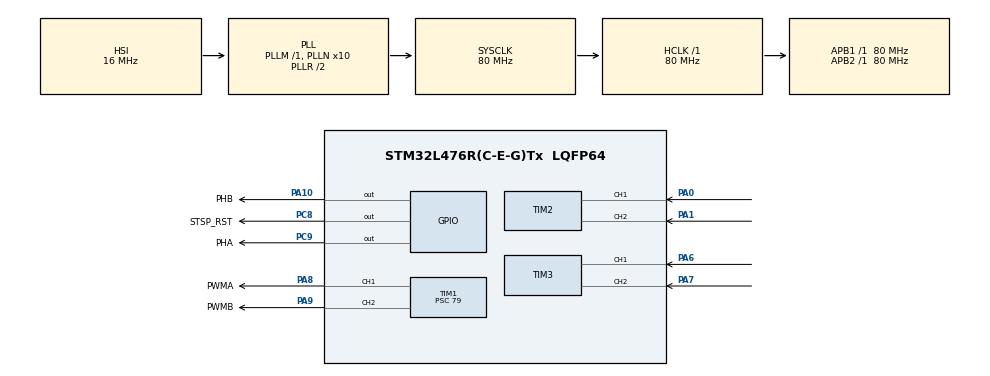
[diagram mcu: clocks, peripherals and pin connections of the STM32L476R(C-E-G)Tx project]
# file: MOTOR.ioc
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Mcu.Family=STM32L4
Mcu.Name=STM32L476R(C-E-G)Tx
Mcu.Package=LQFP64
NVIC.PriorityGroup=NVIC_PRIORITYGROUP_4
PA0.Signal=S_TIM2_CH1
PA1.Signal=S_TIM2_CH2
PA10.GPIO_Label=PHB
PA10.Signal=GPIO_Output
PA13\ (JTMS-SWDIO).Mode=Serial_Wire
PA13\ (JTMS-SWDIO).Signal=SYS_JTMS-SWDIO
PA14\ (JTCK-SWCLK).Mode=Serial_Wire
PA14\ (JTCK-SWCLK).Signal=SYS_JTCK-SWCLK
PA6.Signal=S_TIM3_CH1
PA7.Signal=S_TIM3_CH2
PA8.GPIO_Label=PWMA
PA8.Signal=S_TIM1_CH1
PA9.GPIO_Label=PWMB
PA9.Signal=S_TIM1_CH2
PC8.GPIO_Label=STSP_RST
PC8.Signal=GPIO_Output
PC9.GPIO_Label=PHA
PC9.Signal=GPIO_Output
ProjectManager.HeapSize=0x200
ProjectManager.StackSize=0x400
ProjectManager.TargetToolchain=MDK-ARM V5.32
RCC.ADCFreq_Value=64000000
RCC.AHBFreq_Value=80000000
RCC.APB1Freq_Value=80000000
RCC.APB1TimFreq_Value=80000000
RCC.APB2Freq_Value=80000000
RCC.APB2TimFreq_Value=80000000
RCC.CortexFreq_Value=80000000
RCC.HCLKFreq_Value=80000000
RCC.HSE_VALUE=8000000
RCC.HSI_VALUE=16000000
RCC.LSE_VALUE=32768
RCC.MSI_VALUE=4000000
RCC.PLLN=10
RCC.PLLSourceVirtual=RCC_PLLSOURCE_HSI
RCC.SYSCLKFreq_VALUE=80000000
RCC.SYSCLKSource=RCC_SYSCLKSOURCE_PLLCLK
RCC.USBFreq_Value=64000000
RCC.VCOOutputFreq_Value=160000000
SH.S_TIM1_CH1.0=TIM1_CH1,PWM Generation1 CH1
SH.S_TIM1_CH2.0=TIM1_CH2,PWM Generation2 CH2
SH.S_TIM2_CH1.0=TIM2_CH1,Encoder_Interface
SH.S_TIM2_CH2.0=TIM2_CH2,Encoder_Interface
SH.S_TIM3_CH1.0=TIM3_CH1,Encoder_Interface
SH.S_TIM3_CH2.0=TIM3_CH2,Encoder_Interface
TIM1.Channel-PWM\ Generation1\ CH1=TIM_CHANNEL_1
TIM1.Channel-PWM\ Generation2\ CH2=TIM_CHANNEL_2
TIM1.Prescaler=79
TIM2.EncoderMode=TIM_ENCODERMODE_TI12
TIM3.EncoderMode=TIM_ENCODERMODE_TI12
VP_TIM1_VS_ClockSourceINT.Mode=Internal
board=custom

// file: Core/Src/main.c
/* USER CODE BEGIN Header */
/**
  ******************************************************************************
  * @file           : main.c
  * @brief          : Main program body
  ******************************************************************************
  * @attention
  *
  * Copyright (c) 2026 STMicroelectronics.
  * All rights reserved.
  *
  * This software is licensed under terms that can be found in the LICENSE file
  * in the root directory of this software component.
  * If no LICENSE file comes with this software, it is provided AS-IS.
  *
  ******************************************************************************
  */
/* USER CODE END Header */
#include "main.h"

/* USER CODE BEGIN Includes */
#include "motor.h"
#include "encoder.h"

/* USER CODE END Includes */

TIM_HandleTypeDef htim1;
TIM_HandleTypeDef htim2;
TIM_HandleTypeDef htim3;

/* USER CODE BEGIN PV */
MOTOR MotorA;
MOTOR MotorB;
/* USER CODE END PV */

void SystemClock_Config(void);
static void MX_GPIO_Init(void);
static void MX_TIM1_Init(void);
static void MX_TIM2_Init(void);
static void MX_TIM3_Init(void);

int main(void)
{

  /* MCU Configuration--------------------------------------------------------*/

  /* Reset of all peripherals, Initializes the Flash interface and the Systick. */
  HAL_Init();

  /* Configure the system clock */
  SystemClock_Config();

  /* Initialize all configured peripherals */
  MX_GPIO_Init();
  MX_TIM1_Init();
  MX_TIM2_Init();
  MX_TIM3_Init();
  /* USER CODE BEGIN 2 */
	motor_init(&MotorA, &htim1, TIM_CHANNEL_1, STSP_RST_GPIO_Port, STSP_RST_Pin,
	PHA_GPIO_Port, PHA_Pin, PWMA_GPIO_Port, PWMA_Pin);
	motor_init(&MotorB, &htim1, TIM_CHANNEL_2, STSP_RST_GPIO_Port, STSP_RST_Pin,
	PHB_GPIO_Port, PHB_Pin, PWMB_GPIO_Port, PWMB_Pin);

	enable_motor(&MotorA);
	enable_motor(&MotorB);
  /* USER CODE END 2 */

  /* Infinite loop */
  while (1)
  {

    /* USER CODE BEGIN 3 */
		set_speed(&MotorA, -500);
		set_speed(&MotorB, 500);
  }
  /* USER CODE END 3 */
}

void SystemClock_Config(void)
{
  RCC_OscInitTypeDef RCC_OscInitStruct = {0};
  RCC_ClkInitTypeDef RCC_ClkInitStruct = {0};

  /** Configure the main internal regulator output voltage
  */
  if (HAL_PWREx_ControlVoltageScaling(PWR_REGULATOR_VOLTAGE_SCALE1) != HAL_OK)
  {
    Error_Handler();
  }

  /** Initializes the RCC Oscillators according to the specified parameters
  * in the RCC_OscInitTypeDef structure.
  */
  RCC_OscInitStruct.OscillatorType = RCC_OSCILLATORTYPE_HSI;
  RCC_OscInitStruct.HSIState = RCC_HSI_ON;
  RCC_OscInitStruct.HSICalibrationValue = RCC_HSICALIBRATION_DEFAULT;
  RCC_OscInitStruct.PLL.PLLState = RCC_PLL_ON;
  RCC_OscInitStruct.PLL.PLLSource = RCC_PLLSOURCE_HSI;
  RCC_OscInitStruct.PLL.PLLM = 1;
  RCC_OscInitStruct.PLL.PLLN = 10;
  RCC_OscInitStruct.PLL.PLLP = RCC_PLLP_DIV7;
  RCC_OscInitStruct.PLL.PLLQ = RCC_PLLQ_DIV2;
  RCC_OscInitStruct.PLL.PLLR = RCC_PLLR_DIV2;
  if (HAL_RCC_OscConfig(&RCC_OscInitStruct) != HAL_OK)
  {
    Error_Handler();
  }

  /** Initializes the CPU, AHB and APB buses clocks
  */
  RCC_ClkInitStruct.ClockType = RCC_CLOCKTYPE_HCLK|RCC_CLOCKTYPE_SYSCLK
                              |RCC_CLOCKTYPE_PCLK1|RCC_CLOCKTYPE_PCLK2;
  RCC_ClkInitStruct.SYSCLKSource = RCC_SYSCLKSOURCE_PLLCLK;
  RCC_ClkInitStruct.AHBCLKDivider = RCC_SYSCLK_DIV1;
  RCC_ClkInitStruct.APB1CLKDivider = RCC_HCLK_DIV1;
  RCC_ClkInitStruct.APB2CLKDivider = RCC_HCLK_DIV1;

  if (HAL_RCC_ClockConfig(&RCC_ClkInitStruct, FLASH_LATENCY_4) != HAL_OK)
  {
    Error_Handler();
  }
}

static void MX_TIM1_Init(void)
{

  TIM_ClockConfigTypeDef sClockSourceConfig = {0};
  TIM_MasterConfigTypeDef sMasterConfig = {0};
  TIM_OC_InitTypeDef sConfigOC = {0};
  TIM_BreakDeadTimeConfigTypeDef sBreakDeadTimeConfig = {0};

  htim1.Instance = TIM1;
  htim1.Init.Prescaler = 79;
  htim1.Init.CounterMode = TIM_COUNTERMODE_UP;
  htim1.Init.Period = 65535;
  htim1.Init.ClockDivision = TIM_CLOCKDIVISION_DIV1;
  htim1.Init.RepetitionCounter = 0;
  htim1.Init.AutoReloadPreload = TIM_AUTORELOAD_PRELOAD_DISABLE;
  if (HAL_TIM_Base_Init(&htim1) != HAL_OK)
  {
    Error_Handler();
  }
  sClockSourceConfig.ClockSource = TIM_CLOCKSOURCE_INTERNAL;
  if (HAL_TIM_ConfigClockSource(&htim1, &sClockSourceConfig) != HAL_OK)
  {
    Error_Handler();
  }
  if (HAL_TIM_PWM_Init(&htim1) != HAL_OK)
  {
    Error_Handler();
  }
  sMasterConfig.MasterOutputTrigger = TIM_TRGO_RESET;
  sMasterConfig.MasterOutputTrigger2 = TIM_TRGO2_RESET;
  sMasterConfig.MasterSlaveMode = TIM_MASTERSLAVEMODE_DISABLE;
  if (HAL_TIMEx_MasterConfigSynchronization(&htim1, &sMasterConfig) != HAL_OK)
  {
    Error_Handler();
  }
  sConfigOC.OCMode = TIM_OCMODE_PWM1;
  sConfigOC.Pulse = 0;
  sConfigOC.OCPolarity = TIM_OCPOLARITY_HIGH;
  sConfigOC.OCNPolarity = TIM_OCNPOLARITY_HIGH;
  sConfigOC.OCFastMode = TIM_OCFAST_DISABLE;
  sConfigOC.OCIdleState = TIM_OCIDLESTATE_RESET;
  sConfigOC.OCNIdleState = TIM_OCNIDLESTATE_RESET;
  if (HAL_TIM_PWM_ConfigChannel(&htim1, &sConfigOC, TIM_CHANNEL_1) != HAL_OK)
  {
    Error_Handler();
  }
  if (HAL_TIM_PWM_ConfigChannel(&htim1, &sConfigOC, TIM_CHANNEL_2) != HAL_OK)
  {
    Error_Handler();
  }
  sBreakDeadTimeConfig.OffStateRunMode = TIM_OSSR_DISABLE;
  sBreakDeadTimeConfig.OffStateIDLEMode = TIM_OSSI_DISABLE;
  sBreakDeadTimeConfig.LockLevel = TIM_LOCKLEVEL_OFF;
  sBreakDeadTimeConfig.DeadTime = 0;
  sBreakDeadTimeConfig.BreakState = TIM_BREAK_DISABLE;
  sBreakDeadTimeConfig.BreakPolarity = TIM_BREAKPOLARITY_HIGH;
  sBreakDeadTimeConfig.BreakFilter = 0;
  sBreakDeadTimeConfig.Break2State = TIM_BREAK2_DISABLE;
  sBreakDeadTimeConfig.Break2Polarity = TIM_BREAK2POLARITY_HIGH;
  sBreakDeadTimeConfig.Break2Filter = 0;
  sBreakDeadTimeConfig.AutomaticOutput = TIM_AUTOMATICOUTPUT_DISABLE;
  if (HAL_TIMEx_ConfigBreakDeadTime(&htim1, &sBreakDeadTimeConfig) != HAL_OK)
  {
    Error_Handler();
  }
  HAL_TIM_MspPostInit(&htim1);

}

static void MX_TIM2_Init(void)
{

  TIM_Encoder_InitTypeDef sConfig = {0};
  TIM_MasterConfigTypeDef sMasterConfig = {0};

  htim2.Instance = TIM2;
  htim2.Init.Prescaler = 0;
  htim2.Init.CounterMode = TIM_COUNTERMODE_UP;
  htim2.Init.Period = 4294967295;
  htim2.Init.ClockDivision = TIM_CLOCKDIVISION_DIV1;
  htim2.Init.AutoReloadPreload = TIM_AUTORELOAD_PRELOAD_DISABLE;
  sConfig.EncoderMode = TIM_ENCODERMODE_TI12;
  sConfig.IC1Polarity = TIM_ICPOLARITY_RISING;
  sConfig.IC1Selection = TIM_ICSELECTION_DIRECTTI;
  sConfig.IC1Prescaler = TIM_ICPSC_DIV1;
  sConfig.IC1Filter = 0;
  sConfig.IC2Polarity = TIM_ICPOLARITY_RISING;
  sConfig.IC2Selection = TIM_ICSELECTION_DIRECTTI;
  sConfig.IC2Prescaler = TIM_ICPSC_DIV1;
  sConfig.IC2Filter = 0;
  if (HAL_TIM_Encoder_Init(&htim2, &sConfig) != HAL_OK)
  {
    Error_Handler();
  }
  sMasterConfig.MasterOutputTrigger = TIM_TRGO_RESET;
  sMasterConfig.MasterSlaveMode = TIM_MASTERSLAVEMODE_DISABLE;
  if (HAL_TIMEx_MasterConfigSynchronization(&htim2, &sMasterConfig) != HAL_OK)
  {
    Error_Handler();
  }

}

static void MX_TIM3_Init(void)
{

  TIM_Encoder_InitTypeDef sConfig = {0};
  TIM_MasterConfigTypeDef sMasterConfig = {0};

  htim3.Instance = TIM3;
  htim3.Init.Prescaler = 0;
  htim3.Init.CounterMode = TIM_COUNTERMODE_UP;
  htim3.Init.Period = 65535;
  htim3.Init.ClockDivision = TIM_CLOCKDIVISION_DIV1;
  htim3.Init.AutoReloadPreload = TIM_AUTORELOAD_PRELOAD_DISABLE;
  sConfig.EncoderMode = TIM_ENCODERMODE_TI12;
  sConfig.IC1Polarity = TIM_ICPOLARITY_RISING;
  sConfig.IC1Selection = TIM_ICSELECTION_DIRECTTI;
  sConfig.IC1Prescaler = TIM_ICPSC_DIV1;
  sConfig.IC1Filter = 0;
  sConfig.IC2Polarity = TIM_ICPOLARITY_RISING;
  sConfig.IC2Selection = TIM_ICSELECTION_DIRECTTI;
  sConfig.IC2Prescaler = TIM_ICPSC_DIV1;
  sConfig.IC2Filter = 0;
  if (HAL_TIM_Encoder_Init(&htim3, &sConfig) != HAL_OK)
  {
    Error_Handler();
  }
  sMasterConfig.MasterOutputTrigger = TIM_TRGO_RESET;
  sMasterConfig.MasterSlaveMode = TIM_MASTERSLAVEMODE_DISABLE;
  if (HAL_TIMEx_MasterConfigSynchronization(&htim3, &sMasterConfig) != HAL_OK)
  {
    Error_Handler();
  }

}

static void MX_GPIO_Init(void)
{
  GPIO_InitTypeDef GPIO_InitStruct = {0};

  /* GPIO Ports Clock Enable */
  __HAL_RCC_GPIOA_CLK_ENABLE();
  __HAL_RCC_GPIOC_CLK_ENABLE();

  /*Configure GPIO pin Output Level */
  HAL_GPIO_WritePin(GPIOC, STSP_RST_Pin|PHA_Pin, GPIO_PIN_RESET);

  /*Configure GPIO pin Output Level */
  HAL_GPIO_WritePin(PHB_GPIO_Port, PHB_Pin, GPIO_PIN_RESET);

  /*Configure GPIO pins : STSP_RST_Pin PHA_Pin */
  GPIO_InitStruct.Pin = STSP_RST_Pin|PHA_Pin;
  GPIO_InitStruct.Mode = GPIO_MODE_OUTPUT_PP;
  GPIO_InitStruct.Pull = GPIO_NOPULL;
  GPIO_InitStruct.Speed = GPIO_SPEED_FREQ_LOW;
  HAL_GPIO_Init(GPIOC, &GPIO_InitStruct);

  /*Configure GPIO pin : PHB_Pin */
  GPIO_InitStruct.Pin = PHB_Pin;
  GPIO_InitStruct.Mode = GPIO_MODE_OUTPUT_PP;
  GPIO_InitStruct.Pull = GPIO_NOPULL;
  GPIO_InitStruct.Speed = GPIO_SPEED_FREQ_LOW;
  HAL_GPIO_Init(PHB_GPIO_Port, &GPIO_InitStruct);

}

void Error_Handler(void)
{
  __disable_irq();
  while (1)
  {
  }
}
